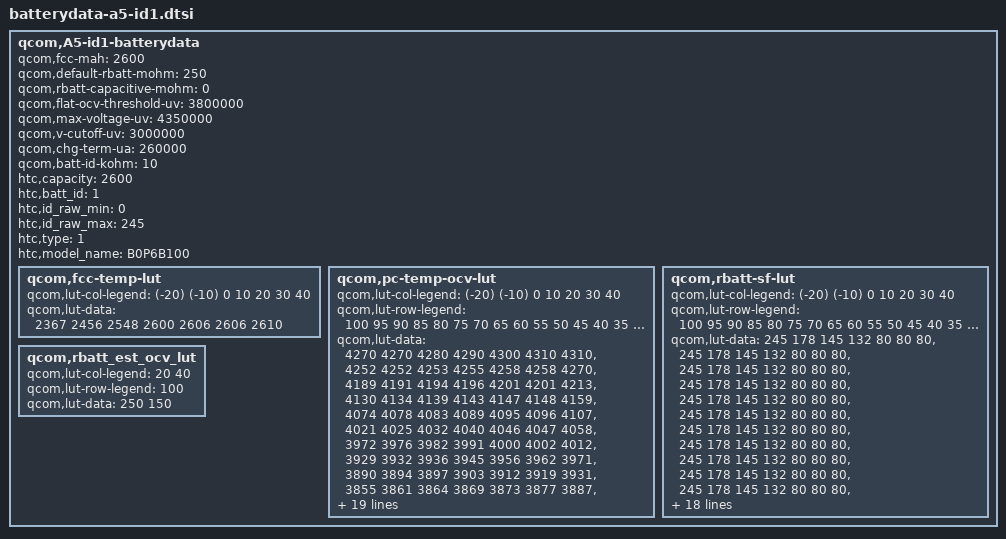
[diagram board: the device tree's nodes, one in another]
qcom,A5-id1-batterydata {
	qcom,fcc-mah = <2600>;
	qcom,default-rbatt-mohm = <250>;
	qcom,rbatt-capacitive-mohm = <0>;
	qcom,flat-ocv-threshold-uv = <3800000>;
	qcom,max-voltage-uv = <4350000>;
	qcom,v-cutoff-uv = <3000000>;
	qcom,chg-term-ua = <260000>;
	qcom,batt-id-kohm = <10>;
	htc,capacity = <2600>;
	htc,batt_id = <1>;
	htc,id_raw_min = <0>;
	htc,id_raw_max = <245>;
	htc,type = <1>;
	htc,model_name = "B0P6B100";

	qcom,fcc-temp-lut {
		qcom,lut-col-legend = <(-20) (-10) 0 10 20 30 40>;
		qcom,lut-data = <2367 2456 2548 2600 2606 2606 2610>;
	};

	qcom,pc-temp-ocv-lut {
		qcom,lut-col-legend = <(-20) (-10) 0 10 20 30 40>;
		qcom,lut-row-legend = <100 95 90 85 80 75 70 65 60 55 50 45 40 35 30 25 20 15 10 9 8 7 6 5 4 3 2 1 0>;
		qcom,lut-data = <4270 4270 4280 4290 4300 4310 4310>,
				<4252 4252 4253 4255 4258 4258 4270>,
				<4189 4191 4194 4196 4201 4201 4213>,
				<4130 4134 4139 4143 4147 4148 4159>,
				<4074 4078 4083 4089 4095 4096 4107>,
				<4021 4025 4032 4040 4046 4047 4058>,
				<3972 3976 3982 3991 4000 4002 4012>,
				<3929 3932 3936 3945 3956 3962 3971>,
				<3890 3894 3897 3903 3912 3919 3931>,
				<3855 3861 3864 3869 3873 3877 3887>,
				<3824 3832 3835 3840 3844 3846 3852>,
				<3797 3808 3810 3817 3819 3822 3827>,
				<3772 3787 3789 3798 3802 3802 3807>,
				<3751 3770 3773 3778 3778 3778 3790>,
				<3731 3755 3758 3762 3762 3762 3775>,
				<3708 3737 3742 3744 3744 3744 3756>,
				<3680 3716 3721 3728 3728 3728 3734>,
				<3691 3691 3691 3703 3703 3703 3703>,
				<3666 3666 3666 3672 3682 3682 3682>,
				<3656 3656 3656 3662 3662 3662 3662>,
				<3646 3646 3646 3652 3652 3652 3652>,
				<3635 3635 3635 3641 3641 3641 3641>,
				<3625 3625 3625 3630 3630 3630 3630>,
				<3610 3615 3615 3620 3627 3627 3627>,
				<3570 3570 3530 3514 3523 3523 3523>,
				<3490 3480 3430 3405 3413 3413 3413>,
				<3370 3360 3300 3278 3282 3282 3282>,
				<3220 3200 3180 3144 3146 3146 3146>,
				<3000 3000 3000 3000 3000 3000 3000>;
	};

	qcom,rbatt-sf-lut {
		qcom,lut-col-legend = <(-20) (-10) 0 10 20 30 40>;
		qcom,lut-row-legend = <100 95 90 85 80 75 70 65 60 55 50 45 40 35 30 25 20 15 10 9 8 7 6 5 4 3 2 1 0>;
		qcom,lut-data = <245 178 145 132 80 80 80>,
				<245 178 145 132 80 80 80>,
				<245 178 145 132 80 80 80>,
				<245 178 145 132 80 80 80>,
				<245 178 145 132 80 80 80>,
				<245 178 145 132 80 80 80>,
				<245 178 145 132 80 80 80>,
				<245 178 145 132 80 80 80>,
				<245 178 145 132 80 80 80>,
				<245 178 145 132 80 80 80>,
				<245 178 145 132 80 80 80>,
				<245 178 145 132 80 80 80>,
				<245 178 145 132 80 80 80>,
				<245 178 145 132 80 80 80>,
				<245 178 145 132 80 80 80>,
				<245 178 145 132 80 80 80>,
				<245 178 145 132 80 80 80>,
				<245 178 145 132 80 80 80>,
				<245 178 145 132 80 80 80>,
				<245 178 145 132 80 80 80>,
				<245 178 145 132 80 80 80>,
				<245 178 145 132 80 80 80>,
				<245 178 145 132 80 80 80>,
				<245 178 145 132 80 80 80>,
				<245 178 145 132 80 80 80>,
				<245 178 145 132 80 80 80>,
				<245 178 145 132 80 80 80>,
                <245 178 145 132 80 80 80>,
				<245 178 145 132 80 80 80>;
	};

	qcom,rbatt_est_ocv_lut {
		qcom,lut-col-legend = <20 40>;
		qcom,lut-row-legend = <100>;
		qcom,lut-data = <250 150>;
	};
};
